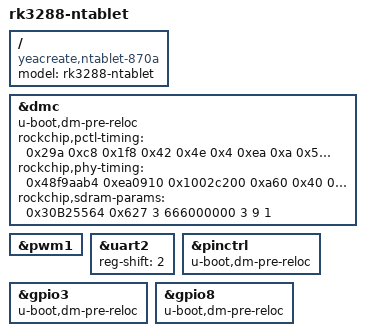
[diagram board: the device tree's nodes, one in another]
/*
 * (C) Copyright 2019 YeaCreate Co., Ltd
 *
 * SPDX-License-Identifier:     GPL-2.0+ X11
 */

/dts-v1/;
#include "rk3288-ntablet-870a.dtsi"
#include "rk3288-u-boot.dtsi"

/ {
	model = "rk3288-ntablet";
	compatible = "yeacreate,ntablet-870a", "rockchip,rk3288";
};

&dmc {
	u-boot,dm-pre-reloc;
	rockchip,pctl-timing = <0x29a 0xc8 0x1f8 0x42 0x4e 0x4 0xea 0xa
		0x5 0x0 0xa 0x7 0x19 0x24 0xa 0x7
		0x5 0xa 0x5 0x200 0x5 0x10 0x40 0x0
		0x1 0x7 0x7 0x4 0xc 0x43 0x100 0x0
		0x5 0x0>;
	rockchip,phy-timing = <0x48f9aab4 0xea0910 0x1002c200
		0xa60 0x40 0x10 0x0>;
	/* Add a dummy value to cause of-platdata think this is bytes */
	rockchip,sdram-params = <0x30B25564 0x627 3 666000000 3 9 1>;
};

&pwm1 {
	status = "okay";
};

&uart2 {
	reg-shift = <2>;
};

&pinctrl {
	u-boot,dm-pre-reloc;
	
};

&gpio3 {
	u-boot,dm-pre-reloc;
};

&gpio8 {
	u-boot,dm-pre-reloc;
};

